AUTOSAR XML (schema 4-3-0)
package /IMU_Interface_ARPkg
  client server interface IF_HALIN_IMU
    operation CSOP_IMUGetOffsetVal
      arg s16_IMUOffsetVal: type=s16_Array6IMUOffsetVal_type, direction=OUT, server-argument-impl-policy=USE-ARGUMENT-TYPE
      arg u8_IMUOffsetValSta: type=uint8, direction=OUT, server-argument-impl-policy=USE-ARGUMENT-TYPE
    operation CSOP_IMUGetSixAxisVal
      arg s16_IMUSixAxisVal: type=s16_Array6IMUSixAxisVal_type, direction=OUT, server-argument-impl-policy=USE-ARGUMENT-TYPE
      arg u8_IMUSixAxisValSta: type=uint8, direction=OUT, server-argument-impl-policy=USE-ARGUMENT-TYPE
    operation CSOP_IMUSetSta
      arg u8_IMUEnaCmd: type=uint8, direction=IN, server-argument-impl-policy=USE-ARGUMENT-TYPE
package /Impl_SWC_IMU_ARPkg
  swc implementation Impl_SWC_IMU_type: programming-language=C, sw-version=1.0.0, vendor-id=0, behavior=SWC_IMU_type_IB
    code-descriptors:
      code SRC: artifact-descriptors=autosar-engineering-object={short-label=EngObject, category=SWSRC}
    resource consumption ResourceConsumption
      memory section Mem_SWC_IMU_CODE: size=0, sw-addrmethod=CODE, symbol=CODE
package /Impl_Type_ARPkg
  impl type s16_Array6IMUOffsetVal_type: category=ARRAY
    element s16_IMUOffsetVal_Element: category=VALUE, array-size=6, array-size-semantics=FIXED-SIZE, base-type=sint16
  impl type s16_Array6IMUSixAxisVal_type: category=ARRAY
    element s16_IMUSixAxisVal_Element: category=VALUE, array-size=6, array-size-semantics=FIXED-SIZE, base-type=sint16
package /SWC_IMU_ARPkg
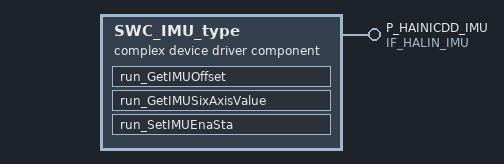
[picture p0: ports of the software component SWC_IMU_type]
  complex device driver sw component type SWC_IMU_type
    provide port P_HAINICDD_IMU: provided-interface=IF_HALIN_IMU
    behavior SWC_IMU_type_IB: handle-termination-and-restart=NO-SUPPORT, port-api-option{enable-take-address=false, indirect-api=false, port=P_HAINICDD_IMU}
      operation invoked event oie_P_HAINICDD_IMU_CSOP_IMUGetOffsetVal: start-on-event=run_GetIMUOffset, operation=P_HAINICDD_IMU.CSOP_IMUGetOffsetVal
      operation invoked event oie_P_HAINICDD_IMU_CSOP_IMUGetSixAxisVal: start-on-event=run_GetIMUSixAxisValue, operation=P_HAINICDD_IMU.CSOP_IMUGetSixAxisVal
      operation invoked event oie_P_HAINICDD_IMU_CSOP_IMUSetSta: start-on-event=run_SetIMUEnaSta, operation=P_HAINICDD_IMU.CSOP_IMUSetSta
      runnable run_GetIMUOffset: symbol=run_HALINCDDIMU
      runnable run_GetIMUSixAxisValue
      runnable run_SetIMUEnaSta
